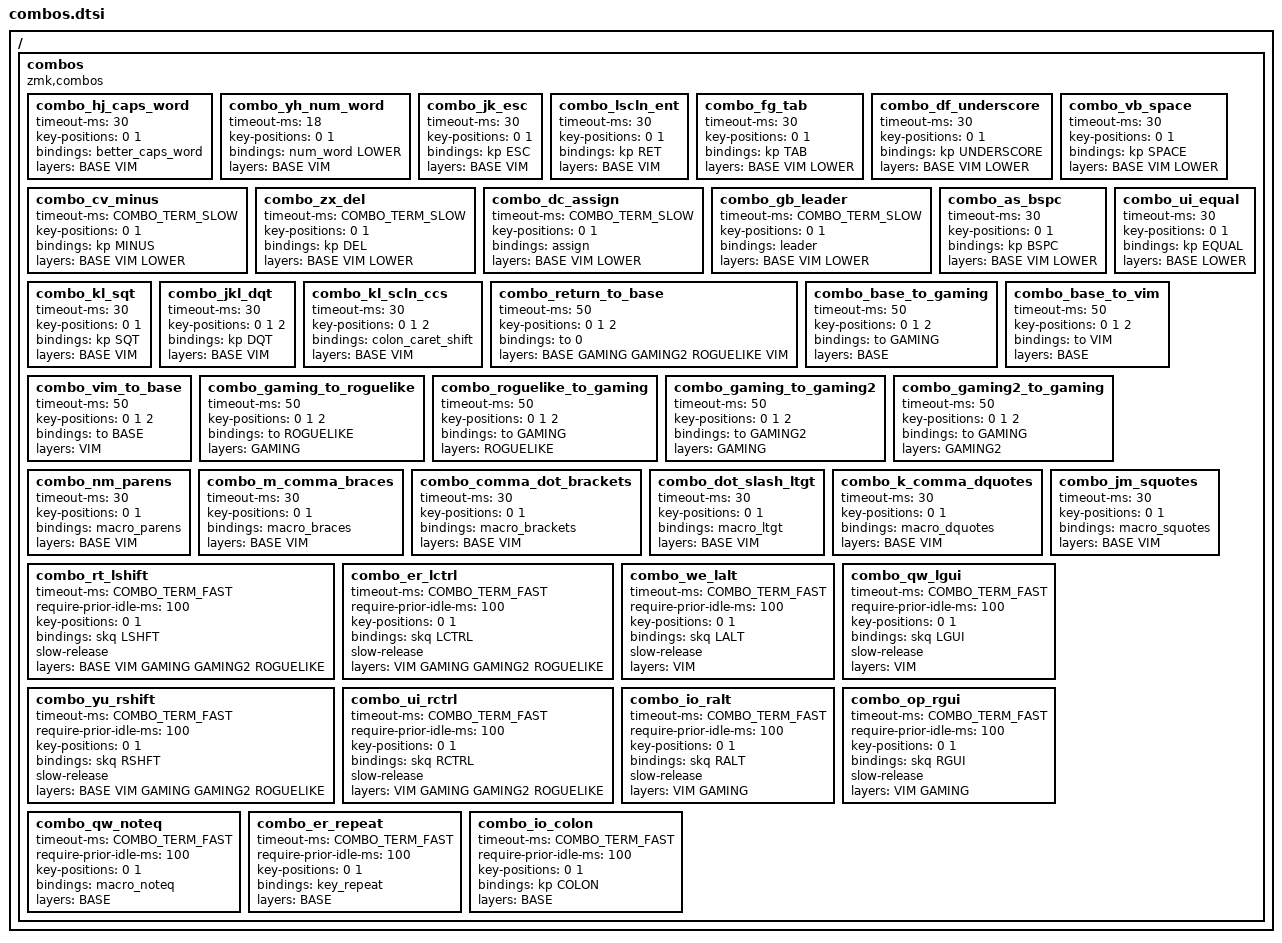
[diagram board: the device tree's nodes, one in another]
// SPDX-License-Identifier: MIT
#include "wrappers.dtsi" // qmk logic. has to come after the zmk headers
#define COMBO_TERM_FAST 18
#define COMBO_TERM_MED 30
#define COMBO_TERM_SLOW 50

/ {
    // clang-format off
    combos {
        compatible = "zmk,combos";
// =====================================================================================
//                         COMBO REFERENCE & EDITING GUIDE
// =====================================================================================
//
//  HOW THIS WORKS
//  All combos defined here with bindings, timeouts, and layer locks.
//  key-positions are PLACEHOLDERS (<0 1>) — override in each board keymap:
//    config/cradio.keymap  (34-key sweep)
//    config/sofle.keymap   (60-key)
//
//  TO ADD A NEW COMBO
//  1. Add the combo node below (copy an existing one as template)
//  2. Set: timeout-ms, bindings, layers  (leave key-positions = <0 1>)
//  3. Override key-positions in EVERY board keymap
//  4. Update this reference table
//
//  POSITION MAPS
//
//  Cradio (34-key):
//   0=Q   1=W   2=E   3=R   4=T │  5=Y   6=U   7=I   8=O   9=P
//  10=A  11=S  12=D  13=F  14=G │ 15=H  16=J  17=K  18=L  19=;
//  20=Z  21=X  22=C  23=V  24=B │ 25=N  26=M  27=,  28=.  29=/
//                        30  31 │ 32  33
//
//  Sofle (60-key):
//   0   1   2   3   4   5       │       6   7   8   9  10  11    ← number row
//  12  13=Q 14=W 15=E 16=R 17=T │ 18=Y 19=U 20=I 21=O 22=P  23
//  24  25=A 26=S 27=D 28=F 29=G │ 30=H 31=J 32=K 33=L 34=;  35
//  36  37=Z 38=X 39=C 40=V 41=B │ 42  43  44=N 45=M 46=, 47=. 48=/ 49
//              50  51  52  53  54 │ 55  56  57  58  59            ← thumbs
//
//  COMBO INDEX
//  ┌────────────────────────┬──────┬────────────┬─────────┬──────────────────┐
//  │ Enum                   │ Keys │ Output     │ Timing  │ Layers           │
//  ├────────────────────────┼──────┼────────────┼─────────┼──────────────────┤
//  │ UTILITY                │      │            │         │                  │
//  │  COMBO_HJ_CAPSWORD     │ H+J  │ CW_TOGG    │ MED     │ BASE VIM         │
//  │  COMBO_YH_NUMWORD      │ Y+H  │ NUMWORD    │ MED     │ BASE VIM         │
//  │  COMBO_JK_ESC          │ J+K  │ KC_ESC     │ MED     │ BASE VIM         │
//  │  COMBO_LSCLN_ENT       │ L+;  │ KC_ENT     │ MED     │ BASE VIM         │
//  │  COMBO_FG_TAB          │ F+G  │ KC_TAB     │ MED     │ BASE VIM LOWER   │
//  │  COMBO_DF_UNDS         │ D+F  │ KC_UNDS    │ MED     │ BASE VIM LOWER   │
//  │  COMBO_VB_SPACE        │ V+B  │ KC_SPACE   │ MED     │ BASE VIM LOWER   │
//  │  COMBO_AS_BSPC         │ A+S  │ KC_BSPC    │ MED     │ BASE VIM LOWER   │
//  │  COMBO_UI_EQUAL        │ U+I  │ KC_EQUAL   │ MED     │ BASE LOWER       │
//  │                        │      │            │         │                  │
//  │  COMBO_CV_MINS         │ C+V  │ KC_MINS    │ SLOW    │ BASE VIM LOWER   │
//  │  COMBO_ZX_DEL          │ Z+X  │ KC_DEL     │ SLOW    │ BASE VIM LOWER   │
//  │  COMBO_DC_ASSEQL       │ D+C  │ :=         │ SLOW    │ BASE VIM LOWER   │
//  │  COMBO_GB_LEADER       │ G+B  │ LEADER     │ SLOW    │ BASE VIM LOWER   │
//  │  // Leader sequences: EM→email, GHN→github, SH→shebang                  │
//  │                        │      │            │         │                  │
//  │  COMBO_KL_SQT          │ K+L  │ KC_QUOT    │ MED     │ BASE VIM         │
//  │  COMBO_JKL_DQT         │ JKL  │ "          │ MED     │ BASE VIM         │
//  │  COMBO_KL_SCLN_CCS     │ KL;  │ : ^ +Shift │ MED     │ BASE VIM         │
//  ├────────────────────────┼──────┼────────────┼─────────┼──────────────────┤
//  │ AUTO-PAIR              │      │            │         │                  │
//  │  COMBO_NM_PARENS       │ N+M  │ () + ←     │ MED     │ BASE VIM         │
//  │  COMBO_MCOMM_BRACES    │ M+,  │ {} + ←     │ MED     │ BASE VIM         │
//  │  COMBO_COMMDOT_BRACKETS│ ,+.  │ [] + ←     │ MED     │ BASE VIM         │
//  │  COMBO_KCOMM_DQUOTES   │ K+,  │ "" + ←     │ MED     │ BASE VIM         │
//  │  COMBO_JM_SQUOTES      │ J+M  │ '' + ←     │ MED     │ BASE VIM         │
//  ├────────────────────────┼──────┼────────────┼─────────┼──────────────────┤
//  │ ONE-SHOT MODS (GACS)   │      │            │         │                  │
//  │  COMBO_RT_OSM_LSFT     │ R+T  │ OSM SHIFT  │ FAST    │ BASE VIM GAM G2 ROG │
//  │  COMBO_YU_OSM_RSFT     │ Y+U  │ OSM SHIFT  │ FAST    │ BASE VIM GAM G2 ROG │
//  │  COMBO_QW_OSM_LGUI     │ Q+W  │ OSM GUI    │ FAST    │ VIM only            │
//  │  COMBO_WE_OSM_LALT     │ W+E  │ OSM ALT    │ FAST    │ VIM only            │
//  │  COMBO_ER_OSM_LCTL     │ E+R  │ OSM CTRL   │ FAST    │ VIM GAM G2 ROG      │
//  │  COMBO_UI_OSM_RCTL     │ U+I  │ OSM CTRL   │ FAST    │ VIM GAM G2 ROG      │
//  │  COMBO_IO_OSM_RALT     │ I+O  │ OSM ALT    │ FAST    │ VIM GAM G2 ROG      │
//  │  COMBO_OP_OSM_RGUI     │ O+P  │ OSM GUI    │ FAST    │ VIM GAM G2 ROG      │
//  ├────────────────────────┼──────┼────────────┼─────────┼──────────────────┤
//  │ BASE TOP ROW           │      │            │         │                  │
//  │  COMBO_QW_NOTEQ        │ Q+W  │ !=         │ FAST    │ BASE             │
//  │  COMBO_ER_REPEAT       │ E+R  │ Repeat     │ FAST    │ BASE             │
//  │  COMBO_IO_COLON        │ I+O  │ KC_COLON   │ FAST    │ BASE             │
//  ├────────────────────────┼──────┼────────────┼─────────┼──────────────────┤
//  │ LAYER SWITCHING        │      │            │         │                  │
//  │  COMBO_QWE_TO_BASE     │ QWE  │ TO(BASE)   │ SLOW    │ !BASE (anywhere) │
//  │  COMBO_ASD_TO_GAMING   │ ASD  │ TO(GAMING) │ SLOW    │ BASE             │
//  │  COMBO_NM_COMM_TO_VIM  │ NM,  │ TO(VIM)    │ SLOW    │ BASE             │
//  │  COMBO_YUI_TO_GAMING2  │ YUI  │ TO(GAMING2)│ SLOW    │ GAMING           │
//  │  COMBO_HJK_TO_ROGUELIKE│ HJK  │ TO(ROGUE)  │ SLOW    │ GAMING           │
//  │  COMBO_YUI_TO_GAMING   │ YUI  │ TO(GAMING) │ SLOW    │ GAMING2          │
//  │  COMBO_HJK_TO_GAMING   │ HJK  │ TO(GAMING) │ SLOW    │ ROGUELIKE        │
//  │  COMBO_NM_COMM_TO_BASE │ NM,  │ TO(BASE)   │ SLOW    │ VIM              │
//  └────────────────────────┴──────┴────────────┴─────────┴──────────────────┘
    // For personal formatting use, templating etc.
//  ┌────────────────────────┬──────┬────────────┬─────────┬──────────────────┐
//  │                        │      │            │         │                  │
//  ├────────────────────────┼──────┼────────────┼─────────┼──────────────────┤
//  ├────────────────────────┼──────┼────────────┼─────────┼──────────────────┤
//  └────────────────────────┴──────┴────────────┴─────────┴──────────────────┘
//  │                        │      │            │         │                  │
//
//  OPEN SLOTS (no combo assigned):
//    2-key:  ZX, XC           (left bottom)
//    3-key:  ZXC, ERT, DFG, CVB, IOP, KL;, ,./
//    vert:   QA, WS, ED, RF, TG, HN, UJ, IK, OL, P;, L., ;/
//    cross:  A;, SL, DK, FJ
//
// =====================================================================================
// Utility combos
// =====================================================================================
        combo_hj_caps_word {
            timeout-ms = <30>;
            key-positions = <0 1>;
            bindings = <&better_caps_word>;
            layers = <BASE VIM>;
        };
        combo_yh_num_word {
            timeout-ms = <18>;
            key-positions = <0 1>;
            bindings = <&num_word LOWER>;
            layers = <BASE VIM>;
        };
        combo_jk_esc {
            timeout-ms = <30>;
            key-positions = <0 1>;
            bindings = <&kp ESC>;
            layers = <BASE VIM>;
        };
        combo_lscln_ent {
            timeout-ms = <30>;
            key-positions = <0 1>;
            bindings = <&kp RET>;
            layers = <BASE VIM>;
        };
        combo_fg_tab {
            timeout-ms = <30>;
            key-positions = <0 1>;
            bindings = <&kp TAB>;
            layers = <BASE VIM LOWER>;
        };
        combo_df_underscore {
            timeout-ms = <30>;
            key-positions = <0 1>;
            bindings = <&kp UNDERSCORE>;
            layers = <BASE VIM LOWER>;
        };
        combo_vb_space {
            timeout-ms = <30>;
            key-positions = <0 1>;
            bindings = <&kp SPACE>;
            layers = <BASE VIM LOWER>;
        };
        combo_cv_minus {
            timeout-ms = <COMBO_TERM_SLOW>;
            key-positions = <0 1>;
            bindings = <&kp MINUS>;
            layers = <BASE VIM LOWER>;
        };
        combo_zx_del {
            timeout-ms = <COMBO_TERM_SLOW>;
            key-positions = <0 1>;
            bindings = <&kp DEL>;
            layers = <BASE VIM LOWER>;
        };
        combo_dc_assign {
            timeout-ms = <COMBO_TERM_SLOW>;
            key-positions = <0 1>;
            bindings = <&assign>;
            layers = <BASE VIM LOWER>;
        };
        combo_gb_leader {
            timeout-ms = <COMBO_TERM_SLOW>;
            key-positions = <0 1>;
            bindings = <&leader>;
            layers = <BASE VIM LOWER>;
        };
        combo_as_bspc {
            timeout-ms = <30>;
            key-positions = <0 1>;
            bindings = <&kp BSPC>;
            layers = <BASE VIM LOWER>;
        };
        combo_ui_equal {
            timeout-ms = <30>;
            key-positions = <0 1>;
            bindings = <&kp EQUAL>;
            layers = <BASE LOWER>;
        };
        combo_kl_sqt {
            timeout-ms = <30>;
            key-positions = <0 1>;
            bindings = <&kp SQT>;
            layers = <BASE VIM>;
        };
        combo_jkl_dqt {
            timeout-ms = <30>;
            key-positions = <0 1 2>;
            bindings = <&kp DQT>;
            layers = <BASE VIM>;
        };
        combo_kl_scln_ccs: combo_kl_scln_ccs {
            timeout-ms = <30>;
            key-positions = <0 1 2>;
            bindings = <&colon_caret_shift>;
            layers = <BASE VIM>;
        };
// =====================================================================================
// Three-finger layer switching combos
// =====================================================================================
        combo_return_to_base {
            timeout-ms = <50>;
            key-positions = <0 1 2>;
            bindings = <&to 0>;
            layers = <BASE GAMING GAMING2 ROGUELIKE VIM>;
        };
        combo_base_to_gaming {
            timeout-ms = <50>;
            key-positions = <0 1 2>;
            bindings = <&to GAMING>;
            layers = <BASE>;
        };
        combo_base_to_vim {
            timeout-ms = <50>;
            key-positions = <0 1 2>;
            bindings = <&to VIM>;
            layers = <BASE>;
        };
        combo_vim_to_base {
            timeout-ms = <50>;
            key-positions = <0 1 2>;
            bindings = <&to BASE>;
            layers = <VIM>;
        };
        combo_gaming_to_roguelike {
            timeout-ms = <50>;
            key-positions = <0 1 2>;
            bindings = <&to ROGUELIKE>;
            layers = <GAMING>;
        };
        combo_roguelike_to_gaming {
            timeout-ms = <50>;
            key-positions = <0 1 2>;
            bindings = <&to GAMING>;
            layers = <ROGUELIKE>;
        };
        combo_gaming_to_gaming2 {
            timeout-ms = <50>;
            key-positions = <0 1 2>;
            bindings = <&to GAMING2>;
            layers = <GAMING>;
        };
        combo_gaming2_to_gaming {
            timeout-ms = <50>;
            key-positions = <0 1 2>;
            bindings = <&to GAMING>;
            layers = <GAMING2>;
        };
// =====================================================================================
// Auto-pair combos — types pair and moves cursor inside
// =====================================================================================
        combo_nm_parens: combo_nm_parens {
            timeout-ms = <30>;
            key-positions = <0 1>;
            bindings = <&macro_parens>;
            layers = <BASE VIM>;
        };
        combo_m_comma_braces: combo_m_comma_braces {
            timeout-ms = <30>;
            key-positions = <0 1>;
            bindings = <&macro_braces>;
            layers = <BASE VIM>;
        };
        combo_comma_dot_brackets: combo_comma_dot_brackets {
            timeout-ms = <30>;
            key-positions = <0 1>;
            bindings = <&macro_brackets>;
            layers = <BASE VIM>;
        };
        combo_dot_slash_ltgt: combo_dot_slash_ltgt {
            timeout-ms = <30>;
            key-positions = <0 1>;
            bindings = <&macro_ltgt>;
            layers = <BASE VIM>;
        };
        combo_k_comma_dquotes: combo_k_comma_dquotes {
            timeout-ms = <30>;
            key-positions = <0 1>;
            bindings = <&macro_dquotes>;
            layers = <BASE VIM>;
        };
        combo_jm_squotes: combo_jm_squotes {
            timeout-ms = <30>;
            key-positions = <0 1>;
            bindings = <&macro_squotes>;
            layers = <BASE VIM>;
        };
// =====================================================================================
// One-shot modifier combos (top row, GACS order)
// For roguelike/gaming layers where HRM timing interferes with frame input
// =====================================================================================
        // Left hand
        combo_rt_lshift: combo_rt_lshift {
            timeout-ms = <COMBO_TERM_FAST>;
            require-prior-idle-ms = <100>;
            key-positions = <0 1>;
            bindings = <&skq LSHFT>;
            slow-release;
            layers = <BASE VIM GAMING GAMING2 ROGUELIKE>;
        };
        combo_er_lctrl: combo_er_lctrl {
            timeout-ms = <COMBO_TERM_FAST>;
            require-prior-idle-ms = <100>;
            key-positions = <0 1>;
            bindings = <&skq LCTRL>;
            slow-release;
            layers = <VIM GAMING GAMING2 ROGUELIKE>;
        };
        combo_we_lalt: combo_we_lalt {
            timeout-ms = <COMBO_TERM_FAST>;
            require-prior-idle-ms = <100>;
            key-positions = <0 1>;
            bindings = <&skq LALT>;
            slow-release;
            layers = <VIM>;
        };
        combo_qw_lgui: combo_qw_lgui {
            timeout-ms = <COMBO_TERM_FAST>;
            require-prior-idle-ms = <100>;
            key-positions = <0 1>;
            bindings = <&skq LGUI>;
            slow-release;
            layers = <VIM>;
        };
// =====================================================================================
        // Right hand
        combo_yu_rshift: combo_yu_rshift {
            timeout-ms = <COMBO_TERM_FAST>;
            require-prior-idle-ms = <100>;
            key-positions = <0 1>;
            bindings = <&skq RSHFT>;
            slow-release;
            layers = <BASE VIM GAMING GAMING2 ROGUELIKE>;
        };
        combo_ui_rctrl: combo_ui_rctrl {
            timeout-ms = <COMBO_TERM_FAST>;
            require-prior-idle-ms = <100>;
            key-positions = <0 1>;
            bindings = <&skq RCTRL>;
            slow-release;
            layers = <VIM GAMING GAMING2 ROGUELIKE>;
        };
        combo_io_ralt: combo_io_ralt {
            timeout-ms = <COMBO_TERM_FAST>;
            require-prior-idle-ms = <100>;
            key-positions = <0 1>;
            bindings = <&skq RALT>;
            slow-release;
            layers = <VIM GAMING>;
        };
        combo_op_rgui: combo_op_rgui {
            timeout-ms = <COMBO_TERM_FAST>;
            require-prior-idle-ms = <100>;
            key-positions = <0 1>;
            bindings = <&skq RGUI>;
            slow-release;
            layers = <VIM GAMING>;
        };
// =====================================================================================
// BASE-only top row combos (same physical keys as VIM OSM mods, layer-filtered)
// =====================================================================================
        combo_qw_noteq {
            timeout-ms = <COMBO_TERM_FAST>;
            require-prior-idle-ms = <100>;
            key-positions = <0 1>;
            bindings = <&macro_noteq>;
            layers = <BASE>;
        };
        combo_er_repeat {
            timeout-ms = <COMBO_TERM_FAST>;
            require-prior-idle-ms = <100>;
            key-positions = <0 1>;
            bindings = <&key_repeat>;
            layers = <BASE>;
        };
        combo_io_colon {
            timeout-ms = <COMBO_TERM_FAST>;
            require-prior-idle-ms = <100>;
            key-positions = <0 1>;
            bindings = <&kp COLON>;
            layers = <BASE>;
        };
// =====================================================================================
// end of combos
// =====================================================================================
    };
};
